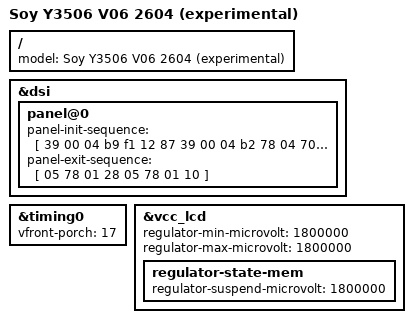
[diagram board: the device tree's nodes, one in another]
// SPDX-License-Identifier: (GPL-2.0+ OR MIT)
/* Experimental Soy Y3506 V06 batch 2604, not hardware-tested.
 * Register and rail facts: dtbvault.com, rk3326-r35s-linux-pGvBnbTz.
 * Stock SHA256: 205c7ef6ea86f81f0e3bb7f1bc042b966b3c51c68cfee44ce17b51966fba43ab
 * Do not use the older 3.3 V Soy-Panel7 profile on this 1.8 V LCD.
 */
/dts-v1/;
#include "rk3326-r36s-clone-soysauce.dtsi"
#include "rk3326-r36s-clone-panel-soy7.dtsi"
/ {
	model = "Soy Y3506 V06 2604 (experimental)";
};
&dsi {
	panel@0 {
		panel-init-sequence = [
			39 00 04 b9 f1 12 87
			39 00 04 b2 78 04 70
			39 00 0b b3 10 10 fc fc 03 ff 00 00 00 00
			15 00 02 b4 80
			39 00 03 b5 0a 0a
			39 00 03 b6 7a 7a
			39 00 05 b8 26 22 f0 13
			39 00 1c ba 33 81 05 f9 0e 0e 20 00 00 00 00 00 00 00 44 25 00 91 0a 00 00 01 4f 01 00 00 37
			15 00 02 bc 47
			39 00 06 bf 02 11 00 80 04
			39 00 0a c0 73 73 50 50 00 00 12 73 00
			39 00 12 c1 73 00 32 32 77 f4 77 77 cc cc ff ff 11 11 00 00 32
			39 00 0d c7 b8 00 0a 10 01 09 00 00 ed c5 00 a5
			39 00 05 c8 10 40 1e 03
			15 00 02 cc 0b
			39 00 23 e0 00 07 0d 3f 3f 3f 44 49 06 0b 0c 0f 13 0f 12 16 1f 00 07 0d 3f 3f 3f 44 49 06 0b 0c 0f 13 0f 12 16 1f
			39 00 08 e1 11 11 91 00 00 00 00
			39 00 0f e3 07 07 0b 0b 0b 0b 00 00 00 00 ff 04 c0 10
			39 00 40 e9 c8 10 02 00 00 b0 b1 11 31 23 28 80 b0 b1 27 08 00 04 02 00 00 00 00 04 02 00 00 00 88 88 ba 60 24 08 88 88 88 88 88 88 88 ba 71 35 18 88 88 88 88 88 00 00 00 01 00 00 00 00 00 00 00 00 00
			39 00 3e ea 97 0a 82 02 03 07 00 00 00 00 00 00 81 88 ba 17 53 88 88 88 88 88 88 80 88 ba 06 42 88 88 88 88 88 88 23 00 00 02 a5 00 00 00 00 00 00 00 00 00 00 00 00 00 00 00 00 00 00 00 00 00 00
			39 00 04 ef ff ff 01
			05 fa 01 11
			05 32 01 29
		];
		panel-exit-sequence = [
			05 78 01 28
			05 78 01 10
		];
	};
};
&timing0 {
	vfront-porch = <17>;
};
&vcc_lcd {
	regulator-min-microvolt = <1800000>;
	regulator-max-microvolt = <1800000>;
	regulator-state-mem {
		regulator-suspend-microvolt = <1800000>;
	};
};
